# ISD9100_v3 register map
File version: 1.0
Registers are 32-bit, read-write, reset 0x0 unless marked. A register's access mark holds for its fields unless they carry their own. Offsets are from the block's base; [hi:lo] are bit positions; 'fields as' and 'values as' point back to an identical list; <NAME> marks a mode.

## PWM — PWMA Register Map
Base 0x40040000
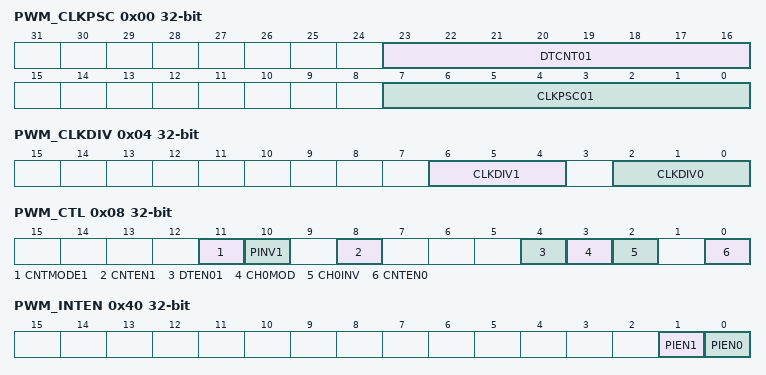
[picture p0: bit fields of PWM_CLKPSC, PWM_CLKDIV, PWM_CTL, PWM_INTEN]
0x00 PWM_CLKPSC — PWM Prescaler Register
  [23:16] DTCNT01 — Dead Zone Interval Register For Pair Of PWM0 And PWM1. These 8 bits determine dead zone length. The unit time of dead zone length is that from clock selector 0.
  [7:0] CLKPSC01 — Clock Pre-scaler. Clock input is divided by (CLKPSC01 + 1). If CLKPSC01 aaa 0, then the pre-scaler output clock will be stopped. This implies PWM counter 0 and 1 will also be stopped.
0x04 PWM_CLKDIV — PWM Clock Select Register
  [6:4] CLKDIV1 — Timer 1 Clock Source Selection. Value : Input clock divided by. 0 : 2. 1 : 4. 2 : 8. 3 : 16. 4 : 1
  [2:0] CLKDIV0 — Timer 0 Clock Source Selection (Table is as CLKDIV1)
0x08 PWM_CTL — PWM Control Register
  [11] CNTMODE1 — PWM-Timer 1 Auto-reload/One-Shot Mode. Note: A rising transition of this bit will cause PWM_PERIOD1 and PWM_CMPDAT1 to be cleared.
    0=One-Shot Mode; 1=Auto-load Mode
  [10] PINV1 — PWM-Timer 1 Output Inverter ON/OFF
    0=Inverter OFF; 1=Inverter ON
  [8] CNTEN1 — PWM-Timer 1 Enable/Disable Start Run
    0=Stop PWM-Timer 1; 1=Enable PWM-Timer 1 Start/Run
  [4] DTEN01 — Dead-Zone 0 Generator Enable/Disable. Note: When Dead-Zone Generator is enabled, the pair of PWM0 and PWM1 become a complementary pair.
    0=Disable; 1=Enable
  [3] CH0MOD — PWM-Timer 0 Auto-reload/One-Shot Mode. Note: A rising transition of this bit will cause PWM_PERIOD0 and PWM_CMPDAT0 to be cleared.
    0=One-Shot Mode; 1=Auto-reload Mode
  [2] CH0INV — PWM-Timer 0 Output Inverter ON/OFF
    0=Inverter OFF; 1=Inverter ON
  [0] CNTEN0 — PWM-Timer 0 Enable/Disable Start Run
    0=Stop PWM-Timer 0 Running; 1=Enable PWM-Timer 0 Start/Run
0x0C PWM_PERIOD0 — PWM Counter Register 0
  [15:0] PERIOD — PWM Counter/Timer Reload Value. PERIOD determines the PWM period. PWM frequency aaa PWM01_CLK/(prescale+1)*(clock divider)/(PERIOD+1); Duty ratio aaa (CMP+1)/(PERIOD+1). CMP > aaa PERIOD: PWM output is always high. CMP < PERIOD: PWM low width aaa (PERIOD-CMP) unit; PWM high width aaa (CMP+1) unit. CMP aaa 0: PWM low width aaa (PERIOD) unit; PWM high width aaa 1 unit (Unit aaa one PWM clock cycle). Note: Any write to PERIOD will take effect in next PWM cycle.
0x10 PWM_CMPDAT0 — PWM Comparator Register 0
  [15:0] CMP — PWM Comparator Register. CMP determines the PWM duty cycle. PWM frequency aaa PWM01_CLK/(prescale+1)*(clock divider)/(PERIOD+1); Duty Cycle aaa (CMP+1)/(PERIOD+1). CMP > aaa PERIOD: PWM output is always high. CMP < PERIOD: PWM low width aaa (PERIOD-CMP) unit; PWM high width aaa (CMP+1) unit. CMP aaa 0: PWM low width aaa (PERIOD) unit; PWM high width aaa 1 unit (Unit aaa one PWM clock cycle). Note: Any write to CMP will take effect in next PWM cycle.
0x14 PWM_CNT0 ro — PWM Data Register 0
  [15:0] CNT — PWM Data Register. Reports the current value of the 16-bit down counter.
0x18 PWM_PERIOD1 — PWM Counter Register 0
  fields as PWM_PERIOD0
0x1C PWM_CMPDAT1 — PWM Comparator Register 0
  fields as PWM_CMPDAT0
0x20 PWM_CNT1 ro — PWM Data Register 0
  fields as PWM_CNT0
0x40 PWM_INTEN — PWM Interrupt Enable Register
  [1] PIEN1 — PWM Timer 1 Interrupt Enable
    0=Disable; 1=Enable
  [0] PIEN0 — PWM Timer 0 Interrupt Enable
    0=Disable; 1=Enable
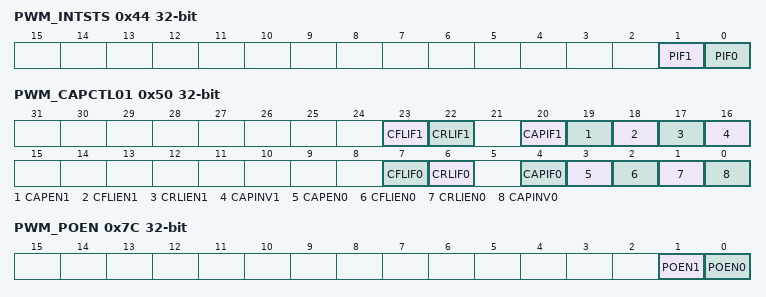
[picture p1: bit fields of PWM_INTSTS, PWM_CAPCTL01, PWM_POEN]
0x44 PWM_INTSTS — PWM Interrupt Flag Register
  [1] PIF1 — PWM Timer 1 Interrupt Flag. Flag is set by hardware when PWM1 down counter reaches zero, software can clear this bit by writing '1' to it.
  [0] PIF0 — PWM Timer 0 Interrupt Flag. Flag is set by hardware when PWM0 down counter reaches zero, software can clear this bit by writing '1' to it.
0x50 PWM_CAPCTL01 — Capture Control Register 0
  [23] CFLIF1 — PWM_FCAPDAT1 Latched Indicator Bit. When input channel 1 has a falling transition, PWM_FCAPDAT1 was latched with the value of PWM down-counter and this bit is set by hardware, software can clear this bit by writing a zero to it.
  [22] CRLIF1 — PWM_RCAPDAT1 Latched Indicator Bit. When input channel 1 has a rising transition, PWM_RCAPDAT1 was latched with the value of PWM down-counter and this bit is set by hardware, software can clear this bit by writing a zero to it.
  [20] CAPIF1 — Capture1 Interrupt Indication Flag. If channel 1 rising latch interrupt is enabled (CRLIEN1 aaa 1), a rising transition at input channel 1 will result in CAPIF1 to high; Similarly, a falling transition will cause CAPIF1 to be set high if channel 1 falling latch interrupt is enabled (CFLIEN1 aaa 1). This flag is cleared by software writing a '1' to it.
  [19] CAPEN1 — Capture Channel 1 Transition Enable/Disable. When enabled, Capture function latches the PMW-counter to RCAPDAT (Rising latch) and FCAPDAT (Falling latch) registers on input edge transition. When disabled, Capture function is inactive as is interrupt.
    0=Disable capture function on channel 1; 1=Enable capture function on channel 1
  [18] CFLIEN1 — Channel 1 Falling Latch Interrupt Enable. When enabled, capture block generates an interrupt on falling edge of input.
    0=Disable falling edge latch interrupt; 1=Enable falling edge latch interrupt
  [17] CRLIEN1 — Channel 1 Rising Latch Interrupt Enable. When enabled, capture block generates an interrupt on rising edge of input.
    0=Disable rising edge latch interrupt; 1=Enable rising edge latch interrupt
  [16] CAPINV1 — Channel 1 Inverter ON/OFF
    0=Inverter OFF; 1=Inverter ON. Reverse the input signal from GPIO before Capture timer
  [7] CFLIF0 — PWM_FCAPDAT0 Latched Indicator Bit. When input channel 0 has a falling transition, PWM_FCAPDAT0 was latched with the value of PWM down-counter and this bit is set by hardware, software can clear this bit by writing a zero to it.
  [6] CRLIF0 — PWM_RCAPDAT0 Latched Indicator Bit. When input channel 0 has a rising transition, PWM_RCAPDAT0 was latched with the value of PWM down-counter and this bit is set by hardware, software can clear this bit by writing a zero to it.
  [4] CAPIF0 — Capture0 Interrupt Indication Flag. If channel 0 rising latch interrupt is enabled (CRLIEN0 aaa 1), a rising transition at input channel 0 will result in CAPIF0 to high; Similarly, a falling transition will cause CAPIF0 to be set high if channel 0 falling latch interrupt is enabled (CFLIEN0 aaa 1). This flag is cleared by software writing a '1' to it.
  [3] CAPEN0 — Capture Channel 0 transition Enable/Disable. When enabled, Capture function latches the PMW-counter to RCAPDAT (Rising latch) and FCAPDAT (Falling latch) registers on input edge transition. When disabled, Capture function is inactive as is interrupt.
    0=Disable capture function on channel 0; 1=Enable capture function on channel 0
  [2] CFLIEN0 — Channel 0 Falling Latch Interrupt Enable ON/OFF. When enabled, capture block generates an interrupt on falling edge of input.
    0=Disable falling latch interrupt; 1=Enable falling latch interrupt
  [1] CRLIEN0 — Channel 0 Rising Latch Interrupt Enable ON/OFF. When enabled, capture block generates an interrupt on rising edge of input.
    0=Disable rising latch interrupt; 1=Enable rising latch interrupt
  [0] CAPINV0 — Channel 0 Inverter ON/OFF
    values as CAPINV1
0x58 PWM_RCAPDAT0 ro — Capture Rising Latch Register (Channel 0)
  [15:0] RCAPDAT — Capture Rising Latch Register. In Capture mode, this register is latched with the value of the PWM counter on a rising edge of the input signal.
0x5C PWM_FCAPDAT0 ro — Capture Falling Latch Register (Channel 0)
  [15:0] FCAPDAT — Capture Falling Latch Register. In Capture mode, this register is latched with the value of the PWM counter on a falling edge of the input signal.
0x60 PWM_RCAPDAT1 ro — Capture Rising Latch Register (Channel 0)
  fields as PWM_RCAPDAT0
0x64 PWM_FCAPDAT1 ro — Capture Falling Latch Register (Channel 0)
  fields as PWM_FCAPDAT0
0x78 PWM_CAPINEN — Capture Input Enable Register
  [1:0] CAPINEN — Capture Input Enable Register. 0 : OFF (PA[13:12] pin input disconnected from Capture block). 1 : ON (PA[13:12] pin, if in PWM alternative function, will be configured as an input and fed to capture function). CAPINEN[1:0]. Bit 10. Bit x1 : Capture channel 0 is from PA [12]. Bit 1x : Capture channel 1 is from PA [13]
0x7C PWM_POEN — PWM Output Enable Register for PWM0~PWM1
  [1] POEN1 — PWM1 Output Enable Register. Note: The corresponding GPIO pin also must be switched to PWM function (refer to SYS_GPA_MFP Table 57)
    0=Disable PWM1 output to pin; 1=Enable PWM1 output to pin
  [0] POEN0 — PWM0 Output Enable Register. Note: The corresponding GPIO pin also must be switched to PWM function (refer to SYS_GPA_MFP Table 57)
    0=Disable PWM0 output to pin; 1=Enable PWM0 output to pin
